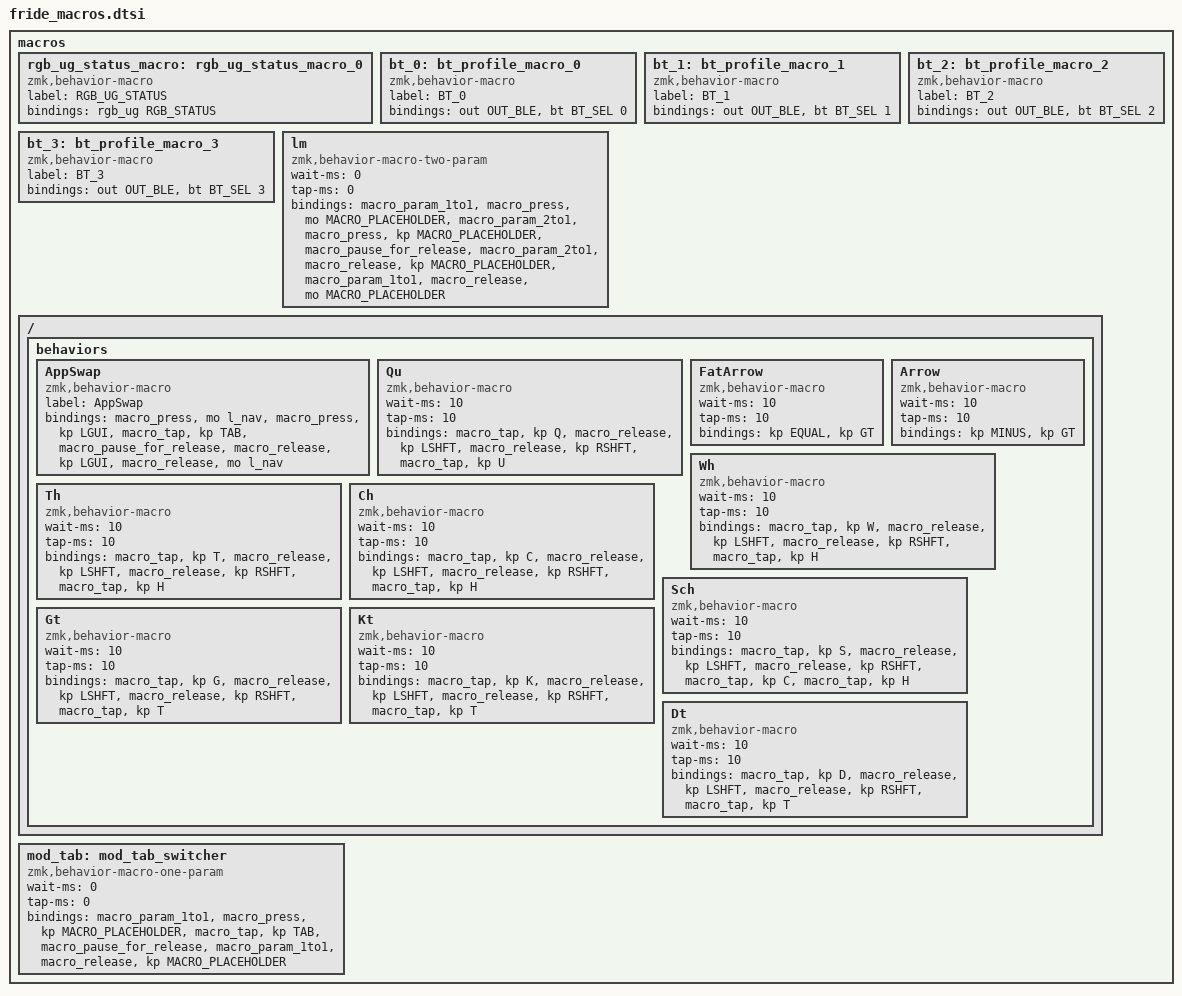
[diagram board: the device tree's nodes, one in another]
 macros {
    rgb_ug_status_macro: rgb_ug_status_macro_0 {
        label = "RGB_UG_STATUS";
        compatible = "zmk,behavior-macro";
        #binding-cells = <0>;
        bindings
            = <&rgb_ug RGB_STATUS>;
    };

    bt_0: bt_profile_macro_0 {
        label = "BT_0";
        compatible = "zmk,behavior-macro";
        #binding-cells = <0>;
        bindings
            = <&out OUT_BLE>,
              <&bt BT_SEL 0>;
    };

    bt_1: bt_profile_macro_1 {
        label = "BT_1";
        compatible = "zmk,behavior-macro";
        #binding-cells = <0>;
        bindings
            = <&out OUT_BLE>,
              <&bt BT_SEL 1>;
    };

    bt_2: bt_profile_macro_2 {
        label = "BT_2";
        compatible = "zmk,behavior-macro";
        #binding-cells = <0>;
        bindings
            = <&out OUT_BLE>,
              <&bt BT_SEL 2>;
    };

    bt_3: bt_profile_macro_3 {
        label = "BT_3";
        compatible = "zmk,behavior-macro";
        #binding-cells = <0>;
        bindings
            = <&out OUT_BLE>,
              <&bt BT_SEL 3>;
    };


    /**
    * Temporarily switches to a layer (`&mo`) while a modifier is held.
    * Analogous to QMK's `LM()`, using a parameterized macro.
    *
    * Params:
    *  1. Layer to switch to
    *  2. Modifier to press while layer is active
    *
    * Example:
    *  `&lm NUM_LAYER LSHIFT`
    */
    lm: lm {
        compatible = "zmk,behavior-macro-two-param";
        wait-ms = <0>;
        tap-ms = <0>;
        #binding-cells = <2>;
        bindings
            = <&macro_param_1to1>
            , <&macro_press &mo MACRO_PLACEHOLDER>
            , <&macro_param_2to1>
            , <&macro_press &kp MACRO_PLACEHOLDER>
            , <&macro_pause_for_release>
            , <&macro_param_2to1>
            , <&macro_release &kp MACRO_PLACEHOLDER>
            , <&macro_param_1to1>
            , <&macro_release &mo MACRO_PLACEHOLDER>
            ;
    };

    ZMK_MACRO(AppSwap,
            label = "AppSwap";
            bindings
            = <&macro_press &mo l_nav>
            , <&macro_press &kp LGUI>
            , <&macro_tap &kp TAB>
            , <&macro_pause_for_release>
            , <&macro_release &kp LGUI>
            , <&macro_release &mo l_nav>
            ;
    )

    ZMK_MACRO(Qu,
        wait-ms = <10>;
        tap-ms = <10>;
        bindings = <&macro_tap &kp Q>
                , <&macro_release &kp LSHFT>
                , <&macro_release &kp RSHFT>
                , <&macro_tap &kp U>
                ;
    )
    mod_tab: mod_tab_switcher {
        compatible = "zmk,behavior-macro-one-param";
        wait-ms = <0>;
        tap-ms = <0>;
        #binding-cells = <1>;
        bindings
            = <&macro_param_1to1>
            , <&macro_press &kp MACRO_PLACEHOLDER>
            , <&macro_tap &kp TAB>
            , <&macro_pause_for_release>
            , <&macro_param_1to1>
            , <&macro_release &kp MACRO_PLACEHOLDER>
            ;
    };

    ZMK_MACRO(FatArrow,
        wait-ms  = <10>;
        tap-ms   = <10>;
        bindings = <&kp EQUAL>
                 , <&kp GT>;
    )

    ZMK_MACRO(Arrow,
        wait-ms = <10>;
        tap-ms = <10>;
        bindings = <&kp MINUS>
                 , <&kp GT>;
    )
    ZMK_MACRO(Wh,
        wait-ms = <10>;
        tap-ms = <10>;
        bindings = <&macro_tap &kp W>
                , <&macro_release &kp LSHFT>
                , <&macro_release &kp RSHFT>
                , <&macro_tap &kp H>
                ;
    )
    ZMK_MACRO(Th,
        wait-ms = <10>;
        tap-ms = <10>;
        bindings = <&macro_tap &kp T>
                , <&macro_release &kp LSHFT>
                , <&macro_release &kp RSHFT>
                , <&macro_tap &kp H>
                ;
    )
       
    ZMK_MACRO(Ch,
        wait-ms = <10>;
        tap-ms = <10>;
        bindings = <&macro_tap &kp C>
                , <&macro_release &kp LSHFT>
                , <&macro_release &kp RSHFT>
                , <&macro_tap &kp H>
                ;
    )
    ZMK_MACRO(Sch,
        wait-ms = <10>;
        tap-ms = <10>;
        bindings = <&macro_tap &kp S>
                , <&macro_release &kp LSHFT>
                , <&macro_release &kp RSHFT>
                , <&macro_tap &kp C>
                , <&macro_tap &kp H>
                ;
    )
    ZMK_MACRO(Gt,
        wait-ms = <10>;
        tap-ms = <10>;
        bindings = <&macro_tap &kp G>
                , <&macro_release &kp LSHFT>
                , <&macro_release &kp RSHFT>
                , <&macro_tap &kp T>
                ;
    )
    ZMK_MACRO(Kt,
        wait-ms = <10>;
        tap-ms = <10>;
        bindings = <&macro_tap &kp K>
                , <&macro_release &kp LSHFT>
                , <&macro_release &kp RSHFT>
                , <&macro_tap &kp T>
                ;
    )
    ZMK_MACRO(Dt,
        wait-ms = <10>;
        tap-ms = <10>;
        bindings = <&macro_tap &kp D>
                , <&macro_release &kp LSHFT>
                , <&macro_release &kp RSHFT>
                , <&macro_tap &kp T>
                ;
    )
 };
